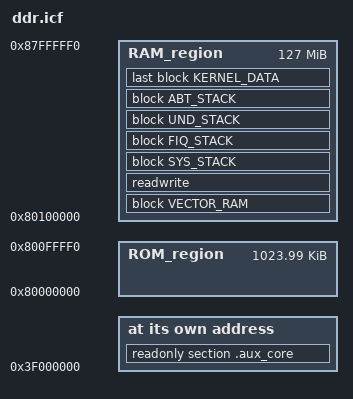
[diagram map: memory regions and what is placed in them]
/* Specials */
define symbol __ICFEDIT_intvec_start__ = 0x80000000;

/* Memory Regions */
define symbol __ICFEDIT_size_bootstack__ = 0x100;
define symbol __ICFEDIT_region_ROM_start__ = 0x80000000;
define symbol __ICFEDIT_region_ROM_end__ = 0x800ffff0;
define symbol __ICFEDIT_region_RAM_start__ = 0x80100000;
define symbol __ICFEDIT_region_RAM_end__ = 0x87fffff0; //128MB = 0x08000000

/* Sizes */
define symbol __ICFEDIT_size_sysstack__ = 0;
define symbol __ICFEDIT_size_fiqstack__ = 0;
define symbol __ICFEDIT_size_undstack__ = 0;
define symbol __ICFEDIT_size_abtstack__ = 0;


define exported symbol __VECTOR_TABLE_ROM_START = 0x00000000;

define exported symbol __DEFAULT_PROCESSOR_NUMBER = 1;
define exported symbol __DEFAULT_INTERRUPT_STACK_SIZE = 0x800;        //1024;
/* 64kB of  shared memory */
define exported symbol __SHARED_RAM_START       = 0x3f040000;
define exported symbol __SHARED_RAM_END         = 0x3f04fff0;
/* 62kB of sram pool */
define exported symbol __SRAM_POOL_START        = 0x3f050000;
define exported symbol __SRAM_POOL_END          = 0x3f07fbf0;
define exported symbol __UNCACHED_DATA_START    = __SRAM_POOL_START;
define exported symbol __UNCACHED_DATA_END      = __SRAM_POOL_END;

/* mem_init writes a storeblock_struct at the end of kernel data, max size 32 bytes */
define exported symbol __BOOT_STACK_ADDRESS = __ICFEDIT_region_RAM_end__ - __ICFEDIT_size_bootstack__;

define exported symbol __KERNEL_DATA_END = __ICFEDIT_region_RAM_end__;

define exported symbol __AUX_CORE_CODE = 0x3f000000;

define memory mem with size = 4G;
define region ROM_region   = mem:[from __ICFEDIT_region_ROM_start__   to __ICFEDIT_region_ROM_end__];
define region RAM_region   = mem:[from __ICFEDIT_region_RAM_start__   to __ICFEDIT_region_RAM_end__];

define block SYS_STACK with alignment = 8, size = __ICFEDIT_size_sysstack__ { };
define block FIQ_STACK with alignment = 8, size = __ICFEDIT_size_fiqstack__ { };
define block UND_STACK with alignment = 8, size = __ICFEDIT_size_undstack__ { };
define block ABT_STACK with alignment = 8, size = __ICFEDIT_size_abtstack__ { };
define block KERNEL_DATA with alignment = 32 { section .kernel_data };
define block VECTOR_ROM with alignment = 32 { section vector_rom };
define block VECTOR_RAM with alignment = 32 { section vector_ram };

initialize by copy { readwrite };
do not initialize  { section .noinit };
do not initialize  { section .kernel_data };

place in ROM_region { first block head { section STARTUP }, readonly, block VECTOR_ROM };
place in RAM_region { block VECTOR_RAM, readwrite, block SYS_STACK, block FIQ_STACK, block UND_STACK, block ABT_STACK, last block KERNEL_DATA };

place at address mem:__AUX_CORE_CODE { readonly section .aux_core };

